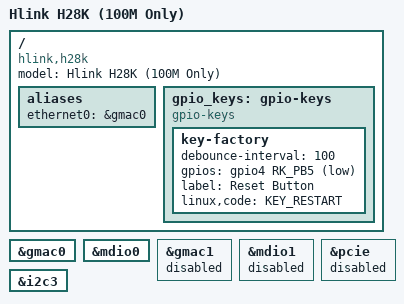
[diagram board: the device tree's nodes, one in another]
// SPDX-License-Identifier: (GPL-2.0+ OR MIT)
/dts-v1/;
#include "rk3528-hlink.dtsi"

/ {
	model = "Hlink H28K (100M Only)";
	compatible = "hlink,h28k", "rockchip,rk3528";

	aliases {
		ethernet0 = &gmac0;
	};

	/* 复位键定义 */
	gpio_keys: gpio-keys {
		compatible = "gpio-keys";
		status = "okay";
		key-factory {
			debounce-interval = <100>;
			gpios = <&gpio4 RK_PB5 GPIO_ACTIVE_LOW>;
			label = "Reset Button";
			linux,code = <KEY_RESTART>;
		};
	};
};

/* 开启百兆网口 */
&gmac0 { status = "okay"; };
&mdio0 { status = "okay"; };

/* 强制关闭不需要的千兆网、MDIO1 和 PCIe */
&gmac1 { status = "disabled"; };
&mdio1 { status = "disabled"; };
&pcie { status = "disabled"; };

&i2c3 { status = "okay"; };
